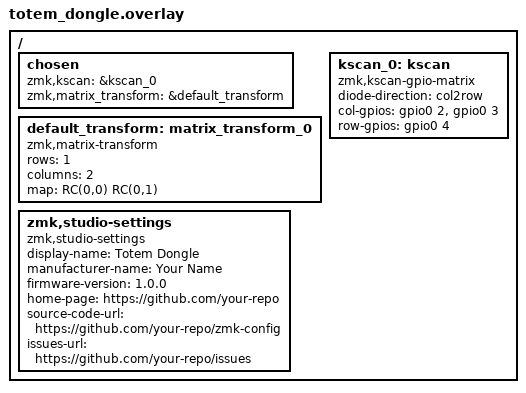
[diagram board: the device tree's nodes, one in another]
#include <dt-bindings/zmk/matrix_transform.h>

/ {
    chosen {
        zmk,kscan = &kscan_0;
        zmk,matrix_transform = &default_transform;
    };

    default_transform: matrix_transform_0 {
        compatible = "zmk,matrix-transform";
        rows = <1>;
        columns = <2>;
        map = <RC(0,0) RC(0,1)>;
    };

    zmk,studio-settings {
        compatible = "zmk,studio-settings";
        display-name = "Totem Dongle";
        manufacturer-name = "Your Name";
        firmware-version = "1.0.0";
        home-page = "https://github.com/your-repo";
        source-code-url = "https://github.com/your-repo/zmk-config";
        issues-url = "https://github.com/your-repo/issues";
    };

    kscan_0: kscan {
        compatible = "zmk,kscan-gpio-matrix";
        diode-direction = "col2row";
        col-gpios = <&gpio0 2 GPIO_ACTIVE_HIGH>,
                   <&gpio0 3 GPIO_ACTIVE_HIGH>;
        row-gpios = <&gpio0 4 GPIO_ACTIVE_HIGH>;
    };
};
